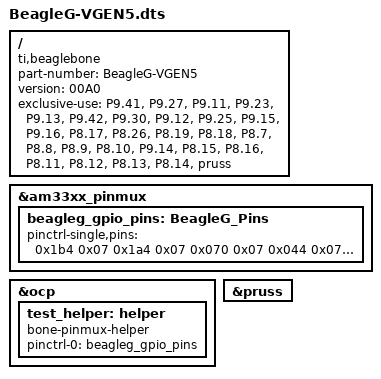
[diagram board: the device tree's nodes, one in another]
/*
 * Copyright (C) 2015 Vision Engraving Systems
 * Copyright (C) 2015 H Hartley Sweeten <hsweeten@visionengravers.com>
 *
 * This program is free software; you can redistribute it and/or modify
 * it under the terms of the GNU General Purpose License Version 2 as
 * published by the Free Software Foundation
 */

/dts-v1/;
/plugin/;

/{
	compatible = "ti,beaglebone", "ti,beaglebone-black";
	part-number = "BeagleG-VGEN5";  /* BeagleG/Vision Gen5 'cape' */
	version = "00A0";

	exclusive-use =
		/* the pins to use ----------------------------------------- */
		"P9.41", "P9.27", "P9.11", "P9.23", "P9.13",		/* STEP signals */
		"P9.42", "P9.30", "P9.12", "P9.25", "P9.15",		/* DIR signals */
		"P9.16", "P8.17", "P8.26", "P8.19", "P8.18",		/* ENA, ESTOP, LED, START, PAUSE */
		"P8.7", "P8.8", "P8.9", "P8.10", "P9.14",		/* OUT signals */
		"P8.15", "P8.16", "P8.11", "P8.12", "P8.13", "P8.14",	/* IN signals */
		/* the hardware to use ------------------------------------- */
		"pruss";						/* Programmable realtime unit */

	fragment@0 {
		target = <&am33xx_pinmux>;
		__overlay__ {
			beagleg_gpio_pins: BeagleG_Pins {
				pinctrl-single,pins = <
					0x1b4 0x07	/* P9.41 CLKOUT2	STEP_0 output	(Mode7: gpio0_20 - gpio20) */
					0x1a4 0x07	/* P9.27 GPIO3_19	STEP_1 output	(Mode7: gpio3_19 - gpio115) */
					0x070 0x07	/* P9.11 UART4_RXD	STEP_2 output	(Mode7: gpio0_30 - gpio30) */
					0x044 0x07	/* P9.23 GPIO1_17	STEP_3 output	(Mode7: gpio1_17 - gpio49) */
					0x074 0x07	/* P9.13 UART4_TXD	STEP_4 output	(Mode7: gpio0_31 - gpio31) */

					0x164 0x07	/* P9.42 GPIO0_7	DIR_0 output	(Mode7: gpio0_7 - gpio7) */
					0x198 0x07	/* P9.30 SPI1_D1	DIR_1 output	(Mode7: gpio3_16 - gpio112) */
					0x078 0x07	/* P9.12 GPIO1_28	DIR_2 output	(Mode7: gpio1_28 - gpio60) */
					0x1ac 0x07	/* P9.25 GPIO3_21	DIR_3 output	(Mode7: gpio3_21 - gpio117) */
					0x040 0x07	/* P9.15 GPIO1_16	DIR_4 output	(Mode7: gpio1_16 - gpio48) */

					0x04c 0x07	/* P9.16 EHRPWM1B	ENA output	(Mode7: gpio1_19 - gpio51) */
					0x02c 0x27	/* P8.17 GPIO0_27	ESTOP input	(Mode7: gpio0_27 - gpio27) */
					0x07c 0x07	/* P8.26 GPIO1_29	LED output	(Mode7: gpio1_29 - gpio61) */
					0x020 0x27	/* P8.19 EHRPWM2A	START input	(Mode7: gpio0_22 - gpio22) */
					0x08c 0x27	/* P8.18 GPIO2_1	PAUSE input	(Mode7: gpio2_1  - gpio65) */

					//0x090 0x07	/* P8.7  TIMER4		OUT0 output	(Mode7: gpio2_2 - gpio66) */
					//0x094 0x07	/* P8.8  TIMER7		OUT1 output	(Mode7: gpio2_3 - gpio67) */
					//0x09c 0x07	/* P8.9  TIMER5		OUT2 output	(Mode7: gpio2_5 - gpio69) */
					//0x098 0x07	/* P8.10 TIMER6		OUT3 output	(Mode7: gpio2_4 - gpio68) */

					0x090 0x02	/* P8.7  TIMER4		OUT0 output	(Mode2: timer4) */
					0x094 0x02	/* P8.8  TIMER7		OUT1 output	(Mode2: timer7) */
					0x09c 0x02	/* P8.9  TIMER5		OUT2 output	(Mode7: timer5) */
					0x098 0x02	/* P8.10 TIMER6		OUT3 output	(Mode7: timer6) */

					0x048 0x07	/* P9.14 EHRPWM1A	OUT4 output	(Mode7: gpio1_18 - gpio50) */

					0x03c 0x27	/* P8.15 GPIO1_15	IN0 input	(Mode7: gpio1_15 - gpio47) */
					0x038 0x27	/* P8.16 GPIO1_14	IN1 input	(Mode7: gpio1_14 - gpio46) */
					0x034 0x27	/* P8.11 GPIO 1_13	IN2 input	(Mode7: gpio1_13 - gpio45) */
					0x030 0x27	/* P8.12 GPIO1_12	IN3 input	(Mode7: gpio1_12 - gpio44) */
					0x024 0x27	/* P8.13 EHRPWM2B	IN4 input	(Mode7: gpio0_23 - gpio23) */
					0x028 0x27	/* P8.14 GPIO0_26	IN5 input	(Mode7: gpio0_26 - gpio26) */
				>;
			};
		};
	};

	fragment@1 {
		target = <&ocp>;
		__overlay__ {
			test_helper: helper {
				compatible = "bone-pinmux-helper";
				pinctrl-names = "default";
				pinctrl-0 = <&beagleg_gpio_pins>;
				status = "okay";
			};
		};
	};

	fragment@2 {
		target = <&pruss>;
		__overlay__ {
			status = "okay";
		};
	};
};
